AUTOSAR XML (schema 00048)
package /ComponentTypes
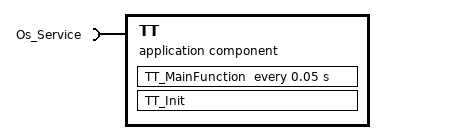
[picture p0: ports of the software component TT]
  application sw component type TT
    require port Os_Service: required-com-specs=[GetElapsedValue, GetCounterValue], required-interface=Os_Service
    behavior TT_InternalBehavior
      timing event TMT_TT_MainFunction: start-on-event=TT_MainFunction, period=0.05
      init event TT_InitEvent: start-on-event=TT_Init
      runnable TT_MainFunction
        sync call SC_Os_Service_GetCounterValue: operation=Os_Service.GetCounterValue
        sync call SC_Os_Service_GetElapsedValue: operation=Os_Service.GetElapsedValue
      runnable TT_Init
  swc implementation TT_Implementation: behavior=TT_InternalBehavior
